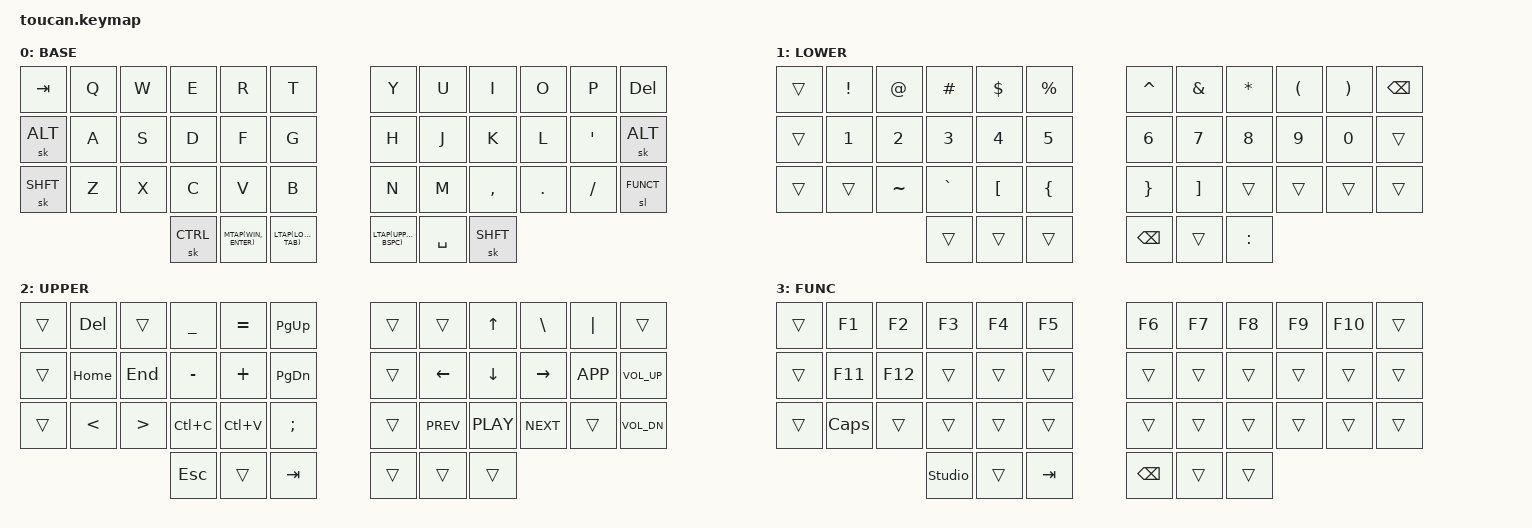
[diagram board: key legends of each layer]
#include <behaviors.dtsi>
#include <dt-bindings/zmk/keys.h>
#include <dt-bindings/zmk/bt.h>
#include <dt-bindings/zmk/outputs.h>
#include <dt-bindings/zmk/pointing.h>


// Basic Layers
#define BASE 0
#define LOWER 1
#define UPPER 2
#define FUNCT  3

// Shift and Control Key Shortened
#define SHFT LSHFT
#define CTRL LCTRL

// ALT/OPT Keys (Win/Mac) (ALT = OPT)
#define ALT LALT
#define OPT LALT

// OS Key (WIN = CMD)
#define WIN LGUI
#define CMD LGUI

// Macro for layer tap
#define LTAP(layer, key) &lt layer key
#define MTAP(mod, key) &mt mod key

// Macro for volume
#define VOL_UP C_VOL_UP
#define VOL_DN C_VOL_DN


/ {
    behaviors {
        td_c_c: tap_dance_command_control {
            compatible = "zmk,behavior-tap-dance";
            #binding-cells = <0>;
            tapping-term-ms = <200>;
            bindings = <&kp CMD>, <&kp CTRL>;
        };

        td_c_w: tap_dance_control_window {
            compatible = "zmk,behavior-tap-dance";
            #binding-cells = <0>;
            tapping-term-ms = <200>;
            bindings = <&kp CTRL>, <&kp WIN>;
        };
    };

    combos {
        compatible = "zmk,combos";
        combo_jk_esc {
            timeout-ms = <50>;
            key-positions = <19 20>;
            bindings = <&kp ESC>;
            layers = <0>;
        };
    };

    macros {
        move_wind: move_window {
            compatible = "zmk,behavior-macro";
            #binding-cells = <0>;
            bindings
                = <&macro_press &kp CTRL>
                , <&macro_press &kp OPT>
                , <&macro_pause_for_release>
                , <&macro_release &kp OPT>
                , <&macro_release &kp CTRL>;
        };

        move_line: move_line {
            compatible = "zmk,behavior-macro";
            #binding-cells = <0>;
            bindings
                = <&macro_press &kp OPT>
                , <&macro_pause_for_release>
                , <&macro_release &kp OPT>;
        };

        cpmv_line: copy_move_line {
            compatible = "zmk,behavior-macro";
            #binding-cells = <0>;
            bindings
                = <&macro_press &kp SHFT>
                , <&macro_press &kp OPT>
                , <&macro_pause_for_release>
                , <&macro_release &kp OPT>
                , <&macro_release &kp SHFT>;
        };
    };

    // Icon Guide
    // ⍂: None
    // ⎕: Transparent
    // ⌻: Held Keys

    // ⍞: Home Key
    // ⍗: Lower Layer Key
    // ⍐: Upper Layer Key
    // ⌺: Function Layer Key
    keymap {
        compatible = "zmk,keymap";

        // 0. BASE
        base {
            display-name = "BASE";

            bindings = <
            //╭───────────┬───────────┬───────────┬───────────┬───────────┬───────────╮       ╭───────────┬───────────┬───────────┬───────────┬───────────┬───────────╮
            //│  Tab      │  Q        │  W        │  E        │  R        │  T        │       │  Y        │  U        │  I        │  O        │  P        │  Del      │
                &kp TAB     &kp Q       &kp W       &kp E       &kp R       &kp T               &kp Y       &kp U       &kp I       &kp O       &kp P       &kp DEL
            //├───────────┼───────────┼───────────┼───────────┼───────────┼───────────┤       ├───────────┼───────────┼───────────┼───────────┼───────────┼───────────┤
            //│  Alt      │  A        │  S        │  D        │  F      ⍞ │  G        │       │  H        │  J      ⍞ │  K        │  L        │  '        │  Alt      │
                &sk ALT     &kp A       &kp S       &kp D       &kp F       &kp G               &kp H       &kp J       &kp K       &kp L       &kp SQT     &sk ALT
            //├───────────┼───────────┼───────────┼───────────┼───────────┼───────────┤       ├───────────┼───────────┼───────────┼───────────┼───────────┼───────────┤
            //│  Shift    │  Z        │  X        │  C        │  V        │  B        │       │  N        │  M        │  ,        │  .        │  /        │  Func   ⌺ │
                &sk SHFT    &kp Z       &kp X       &kp C       &kp V       &kp B               &kp N       &kp M       &kp COMMA   &kp DOT     &kp FSLH    &sl FUNCT
            //├───────────┴───────────┼───────────┴───────────┼───────────┴───────────┤       ├───────────┴───────────┼───────────┴───────────┼───────────┴───────────┤
            //│  Ctrl                 │  Enter                │  Tab                ⍗ │       │  BSpc               ⍐ │  Space                │  Shift                │
                &sk CTRL                MTAP(WIN, ENTER)        LTAP(LOWER, TAB)                LTAP(UPPER, BSPC)       &kp SPACE               &sk SHFT
            //╰───────────────────────┴───────────────────────┴───────────────────────╯       ╰───────────────────────┴───────────────────────┴───────────────────────╯
            >;
        };


        // 1. LOWER
        lower {
            display-name = "LOWER";

            bindings = <
            //╭───────────┬───────────┬───────────┬───────────┬───────────┬───────────╮       ╭───────────┬───────────┬───────────┬───────────┬───────────┬───────────╮
            //│  ⎕        │  !        │  @        │  #        │  $        │  %        │       │  ^        │  &        │  *        │  (        │  )        │  BSpc     │
                &trans      &kp EXCL    &kp AT      &kp HASH    &kp DLLR    &kp PRCNT           &kp CARET   &kp AMPS    &kp STAR    &kp LPAR    &kp RPAR    &kp BSPC
            //├───────────┼───────────┼───────────┼───────────┼───────────┼───────────┤       ├───────────┼───────────┼───────────┼───────────┼───────────┼───────────┤
            //│  ⎕        │  1        │  2        │  3        │  4      ⍞ │  5        │       │  6        │  7      ⍞ │  8        │  9        │  0        │  ⎕        │
                &trans      &kp N1      &kp N2      &kp N3      &kp N4      &kp N5              &kp N6      &kp N7      &kp N8      &kp N9      &kp N0      &trans
            //├───────────┼───────────┼───────────┼───────────┼───────────┼───────────┤       ├───────────┼───────────┼───────────┼───────────┼───────────┼───────────┤
            //│  ⎕        │  ⎕        │  ~        │  `        │  [        │  {        │       │  }        │  ]        │  ⎕        │  ⎕        │  ⎕        │  ⎕        │
                &trans      &trans      &kp TILDE   &kp GRAVE   &kp LBKT    &kp LBRC            &kp RBRC    &kp RBKT    &trans      &trans      &trans      &trans
            //├───────────┴───────────┼───────────┴───────────┼───────────┴───────────┤       ├───────────┴───────────┼───────────┴───────────┼───────────┴───────────┤
            //│  ⎕                    │  ⎕                    │  ⌻                    │       │  BSpc                 │  ⎕                    │  :                    │
                &trans                  &trans                  &trans                          &kp BSPC               &trans                   &kp COLON
            //╰───────────────────────┴───────────────────────┴───────────────────────╯       ╰───────────────────────┴───────────────────────┴───────────────────────╯
            >;
        };


        // 2. UPPER
        upper {
            display-name = "UPPER";

            bindings = <
            //╭───────────┬───────────┬───────────┬───────────┬───────────┬───────────╮       ╭───────────┬───────────┬───────────┬───────────┬───────────┬───────────╮
            //│  ⎕        │  Del      │  ⎕        │  _        │  =        │  PgUp     │       │  ⎕        │  ⎕        │  Up       │  \        │  |        │  ⎕        │
                &trans      &kp DEL     &trans      &kp UNDER   &kp EQUAL   &kp PG_UP           &trans      &trans      &kp UP      &kp BSLH    &kp PIPE    &trans
            //├───────────┼───────────┼───────────┼───────────┼───────────┼───────────┤       ├───────────┼───────────┼───────────┼───────────┼───────────┼───────────┤
            //│  ⎕        │  Home     │  End      │  -        │  +      ⍞ │  PgDn     │       │  ⎕        │  Left   ⍞ │  Down     │  Right    │  Menu     │  VolUp    │
                &trans      &kp HOME    &kp END     &kp MINUS   &kp PLUS    &kp PG_DN           &trans      &kp LEFT    &kp DOWN    &kp RIGHT   &kp K_APP   &kp VOL_UP
            //├───────────┼───────────┼───────────┼───────────┼───────────┼───────────┤       ├───────────┼───────────┼───────────┼───────────┼───────────┼───────────┤
            //│  ⎕        │  <        │  >        │  Copy     │  Paste    │  ;        │       │  ⎕        │  Prev     │  Play     │  Next     │  ⎕        │  VolDn    │
                &trans      &kp LT      &kp GT      &kp LC(C)   &kp LC(V)   &kp SEMI            &trans      &kp C_PREV  &kp C_PLAY  &kp C_NEXT  &trans      &kp VOL_DN
            //├───────────┴───────────┼───────────┴───────────┼───────────────────────┤       ├───────────┴───────────┼───────────┴───────────┼───────────┴───────────┤
            //│  Esc                  │  ⎕                    │  Tab                  │       │  ⌻                    │  ⎕                    │  ⎕                    │
                &kp ESC                 &trans                  &kp TAB                         &trans                  &trans                  &trans
            //╰───────────────────────┴───────────────────────┴───────────────────────╯       ╰───────────────────────┴───────────────────────┴───────────────────────╯
            >;
        };


        // 3. FUNCT
        function {
            display-name = "FUNC";

            bindings = <
            //╭───────────┬───────────┬───────────┬───────────┬───────────┬───────────╮       ╭───────────┬───────────┬───────────┬───────────┬───────────┬───────────╮
            //│  ⎕        │  F1       │  F2       │  F3       │  F4       │  F5       │       │  F6       │  F7       │  F8       │  F9       │  F10      │  ⎕        │
                &trans     &kp F1       &kp F2      &kp F3      &kp F4      &kp F5              &kp F6      &kp F7      &kp F8      &kp F9      &kp F10     &trans
            //├───────────┼───────────┼───────────┼───────────┼───────────┼───────────┤       ├───────────┼───────────┼───────────┼───────────┼───────────┼───────────┤
            //│  ⎕        │  F11      │  F12      │  ⎕        │  ⎕      ⍞ │  ⎕        │       │  ⎕        │  ⎕      ⍞ │  ⎕        │  ⎕        │  ⎕        │  ⎕        │
                &trans      &kp F11     &kp F12     &trans      &trans      &trans              &trans      &trans      &trans      &trans      &trans      &trans
            //├───────────┼───────────┼───────────┼───────────┼───────────┼───────────┤       ├───────────┼───────────┼───────────┼───────────┼───────────┼───────────┤
            //│  ⎕        │  Caps     │  ⎕        │  ⎕        │  ⎕        │  ⎕        │       │  ⎕        │  ⎕        │  ⎕        │  ⎕        │  ⎕        │  ⌻        │
                &trans      &kp CAPS    &trans      &trans      &trans      &trans              &trans      &trans      &trans      &trans      &trans      &trans
            //├───────────┴───────────┼───────────┴───────────┼───────────┴───────────┤       ├───────────┴───────────┼───────────┴───────────┼───────────┴───────────┤
            //│  ⎕                    │  ⎕                    │  Tab                  │       │  BSpc                 │  ⎕                    │  ⎕                    │
                &studio_unlock          &trans                  &kp TAB                         &kp BSPC                &trans                  &trans
            //╰───────────────────────┴───────────────────────┴───────────────────────╯       ╰───────────────────────┴───────────────────────┴───────────────────────╯
            >;
        };
    };
};
